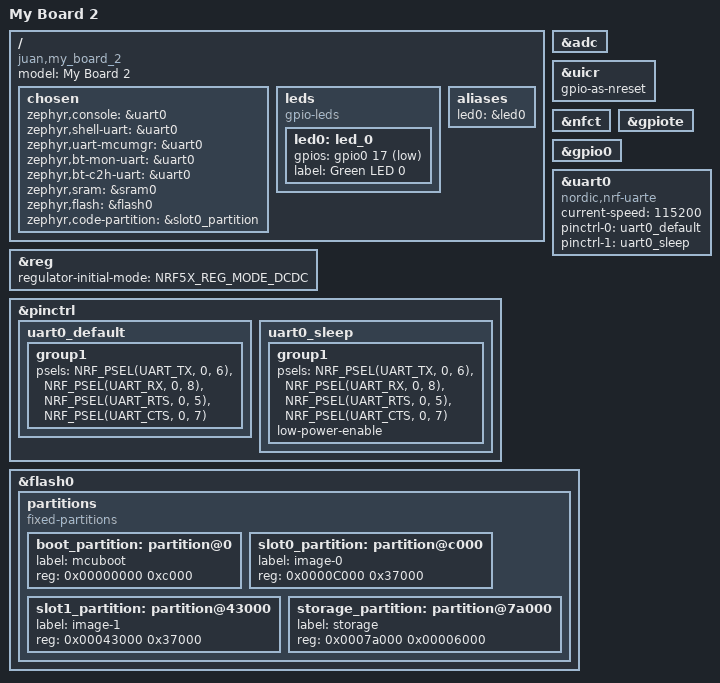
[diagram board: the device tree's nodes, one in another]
/dts-v1/;
#include <nordic/nrf52832_qfaa.dtsi>
#include <zephyr/dt-bindings/input/input-event-codes.h>

/ {
	model = "My Board 2";
	compatible = "juan,my_board_2";

	chosen {
		zephyr,console = &uart0;
		zephyr,shell-uart = &uart0;
		zephyr,uart-mcumgr = &uart0;
		zephyr,bt-mon-uart = &uart0;
		zephyr,bt-c2h-uart = &uart0;
		zephyr,sram = &sram0;
		zephyr,flash = &flash0;
		zephyr,code-partition = &slot0_partition;
	};

	leds {
		compatible = "gpio-leds";

		led0: led_0 {
			gpios = <&gpio0 17 GPIO_ACTIVE_LOW>;
			label = "Green LED 0";
		};
	};

	aliases {
		led0 = &led0;

	};
};


&reg {
	regulator-initial-mode = <NRF5X_REG_MODE_DCDC>;
};

&adc {
	status = "okay";
};

&uicr {
	gpio-as-nreset;
};

&nfct {
	status = "okay";
};

&gpiote {
	status = "okay";
};

&gpio0 {
	status = "okay";
};

&pinctrl {

	uart0_default: uart0_default {
		group1 {
			psels = <NRF_PSEL(UART_TX, 0, 6)>,
				<NRF_PSEL(UART_RX, 0, 8)>,
				<NRF_PSEL(UART_RTS, 0, 5)>,
				<NRF_PSEL(UART_CTS, 0, 7)>;
		};
	};

	uart0_sleep: uart0_sleep {
		group1 {
			psels = <NRF_PSEL(UART_TX, 0, 6)>,
				<NRF_PSEL(UART_RX, 0, 8)>,
				<NRF_PSEL(UART_RTS, 0, 5)>,
				<NRF_PSEL(UART_CTS, 0, 7)>;
			low-power-enable;
		};
	};	
};

arduino_serial: &uart0 {
	status = "okay";
	compatible = "nordic,nrf-uarte";
	current-speed = <115200>;
	pinctrl-0 = <&uart0_default>;
	pinctrl-1 = <&uart0_sleep>;
	pinctrl-names = "default", "sleep";
};

&flash0 {
	partitions {
		compatible = "fixed-partitions";
		#address-cells = <1>;
		#size-cells = <1>;

		boot_partition: partition@0 {
			label = "mcuboot";
			reg = <0x00000000 0xc000>;
		};

		slot0_partition: partition@c000 {
			label = "image-0";
			reg = <0x0000C000 0x37000>;
		};

		slot1_partition: partition@43000 {
			label = "image-1";
			reg = <0x00043000 0x37000>;
		};

		storage_partition: partition@7a000 {
			label = "storage";
			reg = <0x0007a000 0x00006000>;
		};
	};
};
